# PAC52XX register map
Vendor: Active-Semi; Series: PAC52XX; File version: 1.0
CPU: CM0 r0p0, little endian, no MPU, no FPU, vendor SysTick, 2 interrupt priority bits
Registers are 32-bit, read-write, reset 0x0 unless marked. A register's access mark holds for its fields unless they carry their own. Offsets are from the block's base; [hi:lo] are bit positions; 'fields as' and 'values as' point back to an identical list.

## SPI
Base 0x40210000
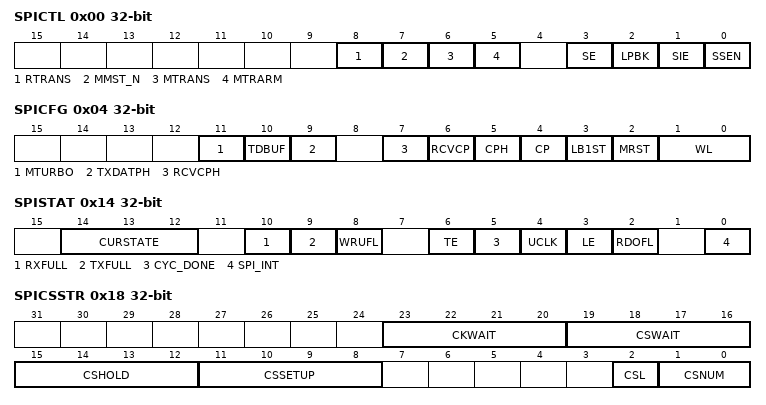
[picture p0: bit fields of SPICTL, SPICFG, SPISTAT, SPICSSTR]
0x00 SPICTL — SPI Control
  [8] RTRANS — Auto-retrans on clock error
    0=enabled (Retransmit on clock error); 1=disabled (No retransmit on clock error)
  [7] MMST_N — Multi-master mode
    0=enabled (Multi-master mode); 1=disabled (Single master mode)
  [6] MTRANS — Multiple transfer mode
    0=single (Generate single transfers); 1=multiple (Generate multiple transfers)
  [5] MTRARM wo — MTRANS re-arm
    1=re-arms the SOCBCTL.MTRANS operation by de-asserting CSx chip select and returning the master mode state machine to IDLE
  [3] SE — Slave enable
    0=disabled (SPI is configured as master); 1=enabled (SPI is configured as slave)
  [2] LPBK — Internal loopback mode
    0=disabled (normal operation); 1=enabled (tie the serial out source to serial in internally (no IO buffers))
  [1] SIE — SPI interrupt enable
    0=disable interrupts; 1=enable interrupts
  [0] SSEN — SPI enable
    0=disable this module; 1=enable this module
0x04 SPICFG — SPI Configuration
  [11] MTURBO — Master "turbo" operation mode
    0=disabled (Legacy operation down to max 8:1 HCLK:SPICLK ratio); 1=enabled (Enable master turbo mode, using HCLK-based bit count allowing operation down to 2:1 HCLK:SPICLK ratio)
  [10] TDBUF — Transmit double-buffer mode
    0=Disable double-buffer, legacy operation with single shift register buffer; 1=Enable double-buffer 'ping-pong' on shift register transmit output path
  [9] TXDATPH — Early transmit data phase
    0=disabled (Normal transmit data phase, transitions on launch edge of SPICLK); 1=enabled (MISO (slave) or MOSI (Master) transitions occur 1/2 a SPICLK period sooner than normal protocol)
  [7] RCVCPH — Slave mode clock phase
    0=1st (First clock transition of a new transfer used to sample data); 1=2nd (Second clock transition of a new transfer used to sample data)
  [6] RCVCP — Slave mode clock polarity
    0=low (SPICLK is low in it's inactive state); 1=high (SPICLK is high in it's inactive state)
  [5] CPH — Master mode clock phase
    0=1st (First clock transition of a new transfer is used to sample data); 1=2nd (Second clock transition of a new transfer is used to sample data)
  [4] CP — Master mode clock polarity
    values as RCVCP
  [3] LB1ST — Least bit first
    0=MSB (MSB is the first serial bit of transfer); 1=LSB (LSB is the first serial bit of transfer)
  [2] MRST — Module reset
    0=disabled (Do not hold module in reset); 1=enabled (Force soft reset of module)
  [1:0] WL — Word length
    0=Word Length = 8-bits; 1=Word Length = 16-bits; 2=Word Length = 24-bits; 3=Word Length = 32-bits
0x08 SPICLKDIV — SPI Clock Divider
  [15:0] CLKDIV — Clock divisor for SCLK (HCLK / (CLKDIV + 1)*2)
0x14 SPISTAT — SPI Status
  [14:12] CURSTATE — Raw status of the SOC bus bridge master state machine's 'current_state' register
    0=IDLE; 1=CSSETUP; 2=TRANSFER; 3=CSHOLD; 4=CSWAIT; 5=CKWAIT; 6=MTRANS; 7=CSBEGIN
  [10] RXFULL — Receive holding register in use
    0=empty (RX incoming holding register contains no valid data word); 1=full (RX incoming holding register contains a valid data word)
  [9] TXFULL — Transmit holding register in use
    0=ready (TX transmit holding register ready to accept data word); 1=not ready (TX transmit holding register in use and not ready)
  [8] WRUFL — Write buffer underflow
    0=none (No write buffer underflow detected since this bit was cleared); 1=underflow (Write buffer underflow detected, write one to clear)
  [6] TE — Chip select trailing edge detect
    0=none (No chip select de-assertion detected since this bit was cleared); 1=detected (Chip select de-assertion was detected, write 1 to clear)
  [5] CYC_DONE — Cycle done (current transfer is complete)
    0=not done (No cycle done detected since this bit was cleared); 1=completed (Cycle done detected, write one to clear)
  [4] UCLK — Underclock condition
    0=none (No underclock detected since this bit was cleared); 1=detected (Underclock condition detected, write 1 to clear)
  [3] LE — Chip select leading edge detect
    0=none (No chip select assertion detected since this bit was cleared); 1=detected (Chip select assertion detected, write 1 to clear)
  [2] RDOFL — Read buffer overflow
    0=none (no read overflow since bit cleared); 1=overflow (read overflow detected, write 1 to clear)
  [0] SPI_INT — SPI interrupt
    0=none (no interrupt); 1=interrupt
0x18 SPICSSTR — SPI Chip Select Steering Register
  [23:20] CKWAIT — SPI clock wait. Only applies if SPICTL.MTRANS=1b(multiple transfers with one chip select assertion). This value determines the minimum number of SPICLK periods to wait between back-to-back transfers. During this wait time, SPICLK does not toggle but CSx remains active.
  [19:16] CSWAIT — Chip select wait. The minimum number of SPICLK periods to wait between the de-assertion of CS<n> and the re-assertion of CS<n>
  [15:12] CSHOLD — Chip select hold. Minimum number of SPICLK periods to wait from the last SPICLK transition to de-assertion of CS<n>
  [11:8] CSSETUP — Chip select setup. Minimum number of SPICLK periods to wait from assertion of CS<n> to the first SPICLK transition
  [2] CSL — Chip select active high level select
    0=Active-low outgoing (master) or incoming (slave) chip select; 1=Active-high outgoing (master) or incoming (slave) ship select
  [1:0] CSNUM — Chip select number
    0=SPICS0; 1=SPICS1; 2=SPICS2
0x1C SPID — SPI Data. On READ, retrieve received data word from the incoming holding buffer. On WRITE, write address or data word to the outgoing holding buffer
  [7:0] DATA — SOC bus bridge data
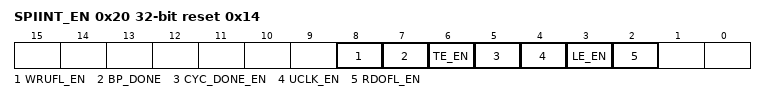
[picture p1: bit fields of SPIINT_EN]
0x20 SPIINT_EN reset 0x14 — SPI Interrupt Enable
  [8] WRUFL_EN — Write buffer underflow SOCBSTAT.WRUFL interrupt enable
    0=disable SOCBSTAT.WRUFL interrupt; 1=enable SOCBSTAT.WRUFL interrupt
  [7] BP_DONE — Byte packing BP_DONE interrupt enable
    0=disable SOCBSTAT. BP_DONE interrupt; 1=enable SOCBSTAT.BP_DONE interrupt
  [6] TE_EN — Trailing edge detect TE interrupt enable
    0=disable SOCBSTAT.TE interrupt; 1=enable SOCBSTAT.TE interrupt
  [5] CYC_DONE_EN — Cycle done CYC_DONE interrupt enable
    0=disable SOCBSTAT.CYC_DONE interrupt; 1=enable SOCBSTAT.CYC_DONE interrupt
  [4] UCLK_EN — Underclock UCLK interrupt enable
    0=disable SOCBSTAT.UCLK interrupt; 1=enable SOCBSTAT.UCLK interrupt
  [3] LE_EN — Leading edge detect LE interrupt enable
    0=disable SOCBSTAT.LE interrupt; 1=enable SOCBSTAT.LE interrupt
  [2] RDOFL_EN — Read buffer overflow RDOFL interrupt enable
    0=disable SOCBSTAT.RDOFL interrupt; 1=enable SOCBSTAT.RDOFL interrupt
